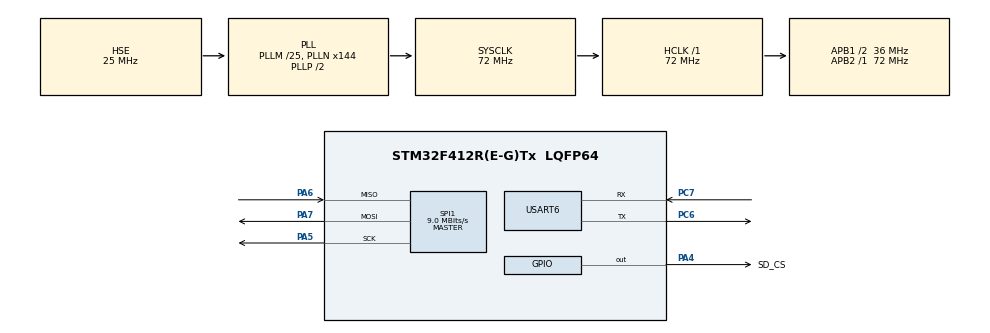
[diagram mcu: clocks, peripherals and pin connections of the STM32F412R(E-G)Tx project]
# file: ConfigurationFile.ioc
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FATFS._MAX_SS=4096
FATFS._USE_LFN=1
Mcu.Family=STM32F4
Mcu.Name=STM32F412R(E-G)Tx
Mcu.Package=LQFP64
NVIC.PriorityGroup=NVIC_PRIORITYGROUP_4
PA13.Mode=Serial_Wire
PA13.Signal=SYS_JTMS-SWDIO
PA14.Mode=Serial_Wire
PA14.Signal=SYS_JTCK-SWCLK
PA4.GPIO_Label=SD_CS
PA4.Signal=GPIO_Output
PA5.Mode=Full_Duplex_Master
PA5.Signal=SPI1_SCK
PA6.Mode=Full_Duplex_Master
PA6.Signal=SPI1_MISO
PA7.Mode=Full_Duplex_Master
PA7.Signal=SPI1_MOSI
PC6.Mode=Asynchronous
PC6.Signal=USART6_TX
PC7.Mode=Asynchronous
PC7.Signal=USART6_RX
PH0\ -\ OSC_IN.Mode=HSE-External-Oscillator
PH0\ -\ OSC_IN.Signal=RCC_OSC_IN
PH1\ -\ OSC_OUT.Mode=HSE-External-Oscillator
PH1\ -\ OSC_OUT.Signal=RCC_OSC_OUT
ProjectManager.HeapSize=0x200
ProjectManager.StackSize=0x400
ProjectManager.TargetToolchain=STM32CubeIDE
RCC.AHBFreq_Value=72000000
RCC.APB1CLKDivider=RCC_HCLK_DIV2
RCC.APB1Freq_Value=36000000
RCC.APB1TimFreq_Value=72000000
RCC.APB2Freq_Value=72000000
RCC.APB2TimFreq_Value=72000000
RCC.CortexFreq_Value=72000000
RCC.HCLKFreq_Value=72000000
RCC.HSE_VALUE=25000000
RCC.PLLM=25
RCC.PLLN=144
RCC.PLLSourceVirtual=RCC_PLLSOURCE_HSE
RCC.SYSCLKFreq_VALUE=72000000
RCC.SYSCLKSource=RCC_SYSCLKSOURCE_PLLCLK
RCC.USBFreq_Value=72000000
RCC.VCOOutputFreq_Value=144000000
SPI1.BaudRatePrescaler=SPI_BAUDRATEPRESCALER_8
SPI1.CalculateBaudRate=9.0 MBits/s
SPI1.Direction=SPI_DIRECTION_2LINES
SPI1.Mode=SPI_MODE_MASTER
SPI1.VirtualType=VM_MASTER
USART6.VirtualMode=VM_ASYNC
VP_FATFS_VS_Generic.Mode=User_defined
board=custom

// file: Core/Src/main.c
/* USER CODE BEGIN Header */
/**
  ******************************************************************************
  * @file           : main.c
  * @brief          : Main program body
  ******************************************************************************
  * @attention
  *
  * Copyright (c) 2023 STMicroelectronics.
  * All rights reserved.
  *
  * This software is licensed under terms that can be found in the LICENSE file
  * in the root directory of this software component.
  * If no LICENSE file comes with this software, it is provided AS-IS.
  *
  ******************************************************************************
  */
/* USER CODE END Header */
#include "main.h"
#include "fatfs.h"

/* USER CODE BEGIN Includes */
#include "fatfs_sd.h"
#include "ConfigurationParser.h"
/* USER CODE END Includes */

SPI_HandleTypeDef hspi1;

UART_HandleTypeDef huart6;

void SystemClock_Config(void);
static void MX_GPIO_Init(void);
static void MX_SPI1_Init(void);
static void MX_USART6_UART_Init(void);

int main(void)
{
  /* USER CODE BEGIN 1 */
  FATFS fs;
  FRESULT fresult;

  /* USER CODE END 1 */

  /* MCU Configuration--------------------------------------------------------*/

  /* Reset of all peripherals, Initializes the Flash interface and the Systick. */
  HAL_Init();

  /* USER CODE BEGIN Init */
  GeneralCard Card;
  RawConfig Config;
  /* USER CODE END Init */

  /* Configure the system clock */
  SystemClock_Config();

  /* Initialize all configured peripherals */
  MX_GPIO_Init();
  MX_SPI1_Init();
  MX_USART6_UART_Init();
  MX_FATFS_Init();
  /* USER CODE BEGIN 2 */
  HAL_UART_Init(&huart6);

  fresult = f_mount(&fs,"",0);
  if (fresult != FR_OK)
	Error_Handler();

  ReadConfigFile(&Config);
  Parser(&Card,&Config);

  /* USER CODE END 2 */

  /* Infinite loop */
  while (1)
  {

  }
}

void SystemClock_Config(void)
{
  RCC_OscInitTypeDef RCC_OscInitStruct = {0};
  RCC_ClkInitTypeDef RCC_ClkInitStruct = {0};

  /** Configure the main internal regulator output voltage
  */
  __HAL_RCC_PWR_CLK_ENABLE();
  __HAL_PWR_VOLTAGESCALING_CONFIG(PWR_REGULATOR_VOLTAGE_SCALE1);

  /** Initializes the RCC Oscillators according to the specified parameters
  * in the RCC_OscInitTypeDef structure.
  */
  RCC_OscInitStruct.OscillatorType = RCC_OSCILLATORTYPE_HSE;
  RCC_OscInitStruct.HSEState = RCC_HSE_ON;
  RCC_OscInitStruct.PLL.PLLState = RCC_PLL_ON;
  RCC_OscInitStruct.PLL.PLLSource = RCC_PLLSOURCE_HSE;
  RCC_OscInitStruct.PLL.PLLM = 25;
  RCC_OscInitStruct.PLL.PLLN = 144;
  RCC_OscInitStruct.PLL.PLLP = RCC_PLLP_DIV2;
  RCC_OscInitStruct.PLL.PLLQ = 2;
  RCC_OscInitStruct.PLL.PLLR = 2;
  if (HAL_RCC_OscConfig(&RCC_OscInitStruct) != HAL_OK)
  {
    Error_Handler();
  }

  /** Initializes the CPU, AHB and APB buses clocks
  */
  RCC_ClkInitStruct.ClockType = RCC_CLOCKTYPE_HCLK|RCC_CLOCKTYPE_SYSCLK
                              |RCC_CLOCKTYPE_PCLK1|RCC_CLOCKTYPE_PCLK2;
  RCC_ClkInitStruct.SYSCLKSource = RCC_SYSCLKSOURCE_PLLCLK;
  RCC_ClkInitStruct.AHBCLKDivider = RCC_SYSCLK_DIV1;
  RCC_ClkInitStruct.APB1CLKDivider = RCC_HCLK_DIV2;
  RCC_ClkInitStruct.APB2CLKDivider = RCC_HCLK_DIV1;

  if (HAL_RCC_ClockConfig(&RCC_ClkInitStruct, FLASH_LATENCY_2) != HAL_OK)
  {
    Error_Handler();
  }
}

static void MX_SPI1_Init(void)
{

  /* SPI1 parameter configuration*/
  hspi1.Instance = SPI1;
  hspi1.Init.Mode = SPI_MODE_MASTER;
  hspi1.Init.Direction = SPI_DIRECTION_2LINES;
  hspi1.Init.DataSize = SPI_DATASIZE_8BIT;
  hspi1.Init.CLKPolarity = SPI_POLARITY_LOW;
  hspi1.Init.CLKPhase = SPI_PHASE_1EDGE;
  hspi1.Init.NSS = SPI_NSS_SOFT;
  hspi1.Init.BaudRatePrescaler = SPI_BAUDRATEPRESCALER_8;
  hspi1.Init.FirstBit = SPI_FIRSTBIT_MSB;
  hspi1.Init.TIMode = SPI_TIMODE_DISABLE;
  hspi1.Init.CRCCalculation = SPI_CRCCALCULATION_DISABLE;
  hspi1.Init.CRCPolynomial = 10;
  if (HAL_SPI_Init(&hspi1) != HAL_OK)
  {
    Error_Handler();
  }

}

static void MX_USART6_UART_Init(void)
{

  huart6.Instance = USART6;
  huart6.Init.BaudRate = 115200;
  huart6.Init.WordLength = UART_WORDLENGTH_8B;
  huart6.Init.StopBits = UART_STOPBITS_1;
  huart6.Init.Parity = UART_PARITY_NONE;
  huart6.Init.Mode = UART_MODE_TX_RX;
  huart6.Init.HwFlowCtl = UART_HWCONTROL_NONE;
  huart6.Init.OverSampling = UART_OVERSAMPLING_16;
  if (HAL_UART_Init(&huart6) != HAL_OK)
  {
    Error_Handler();
  }

}

static void MX_GPIO_Init(void)
{
  GPIO_InitTypeDef GPIO_InitStruct = {0};

  /* GPIO Ports Clock Enable */
  __HAL_RCC_GPIOH_CLK_ENABLE();
  __HAL_RCC_GPIOA_CLK_ENABLE();
  __HAL_RCC_GPIOC_CLK_ENABLE();

  /*Configure GPIO pin Output Level */
  HAL_GPIO_WritePin(SD_CS_GPIO_Port, SD_CS_Pin, GPIO_PIN_RESET);

  /*Configure GPIO pin : SD_CS_Pin */
  GPIO_InitStruct.Pin = SD_CS_Pin;
  GPIO_InitStruct.Mode = GPIO_MODE_OUTPUT_PP;
  GPIO_InitStruct.Pull = GPIO_NOPULL;
  GPIO_InitStruct.Speed = GPIO_SPEED_FREQ_LOW;
  HAL_GPIO_Init(SD_CS_GPIO_Port, &GPIO_InitStruct);

}

void Error_Handler(void)
{
  __disable_irq();
  while (1)
  {
  }
}
